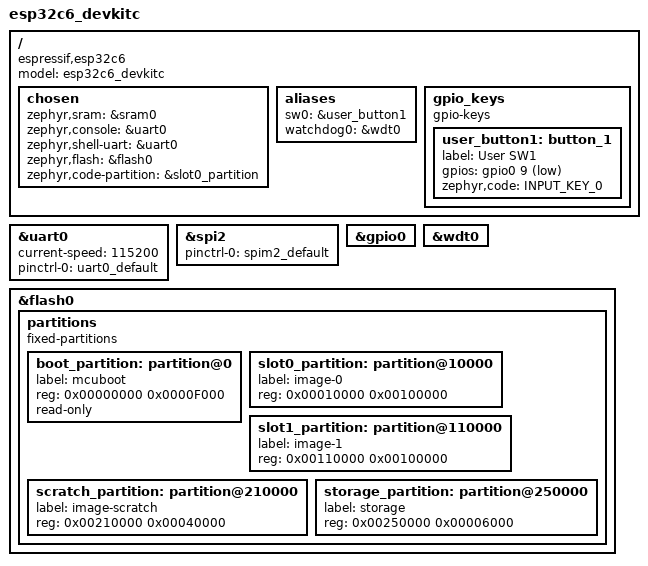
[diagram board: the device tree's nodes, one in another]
/*
 * Copyright (c) 2023 Espressif Systems (Shanghai) Co., Ltd.
 *
 * SPDX-License-Identifier: Apache-2.0
 */

/dts-v1/;

#include <espressif/esp32c6/esp32c6_wroom_n8.dtsi>
#include "esp32c6_devkitc-pinctrl.dtsi"
#include <zephyr/dt-bindings/input/input-event-codes.h>

/ {
	model = "esp32c6_devkitc";
	compatible = "espressif,esp32c6";

	chosen {
		zephyr,sram = &sram0;
		zephyr,console = &uart0;
		zephyr,shell-uart = &uart0;
		zephyr,flash = &flash0;
		zephyr,code-partition = &slot0_partition;
	};

	aliases {
		sw0 = &user_button1;
		watchdog0 = &wdt0;
	};

	gpio_keys {
		compatible = "gpio-keys";
		user_button1: button_1 {
			label = "User SW1";
			gpios = <&gpio0 9 (GPIO_PULL_UP | GPIO_ACTIVE_LOW)>;
			zephyr,code = <INPUT_KEY_0>;
		};
	};
};

&uart0 {
	status = "okay";
	current-speed = <115200>;
	pinctrl-0 = <&uart0_default>;
	pinctrl-names = "default";
};

&spi2 {
	#address-cells = <1>;
	#size-cells = <0>;
	status = "okay";
	pinctrl-0 = <&spim2_default>;
	pinctrl-names = "default";
};

&gpio0 {
	status = "okay";
};

&wdt0 {
	status = "okay";
};

&flash0 {
	status = "okay";
	partitions {
		compatible = "fixed-partitions";
		#address-cells = <1>;
		#size-cells = <1>;

		/* Reserve 60kB for the bootloader */
		boot_partition: partition@0 {
			label = "mcuboot";
			reg = <0x00000000 0x0000F000>;
			read-only;
		};

		/* Reserve 1024kB for the application in slot 0 */
		slot0_partition: partition@10000 {
			label = "image-0";
			reg = <0x00010000 0x00100000>;
		};

		/* Reserve 1024kB for the application in slot 1 */
		slot1_partition: partition@110000 {
			label = "image-1";
			reg = <0x00110000 0x00100000>;
		};

		/* Reserve 256kB for the scratch partition */
		scratch_partition: partition@210000 {
			   label = "image-scratch";
			   reg = <0x00210000 0x00040000>;
		};

		storage_partition: partition@250000 {
			label = "storage";
			reg = <0x00250000 0x00006000>;
		};
	};
};
